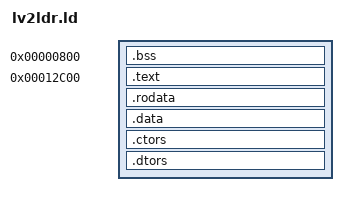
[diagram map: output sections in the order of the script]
ENTRY(_start)

SECTIONS
{
  . = 0x800;

  .bss :
  {
    */lv2ldr/src/loader_global.o(.bss.g_loader)
    */lv2ldr/src/loader_data.o(.bss.g_revoke_list)
    */lv2ldr/src/loader_data.o(.bss.g_auth_area)
    */lv2ldr/src/auth_data.o(.bss.g_revoke_buf)
    */lv2ldr/src/auth_data.o(.bss.g_revoke_digest)
    */lv1ldr/src/auth_buffers.o(.bss.g_part_area)
    */lv1ldr/src/auth_buffers.o(.bss.g_part_digest)
    */lv1ldr/src/auth_buffers.o(.bss.g_header)
    */lv1ldr/src/auth_transfer.o(.bss.g_inf_tail)
    */isoldr/src/hmac_digest.o(.bss.g_hmac)
    */lv1ldr/src/auth_transfer.o(.bss.g_inf_offset)
    */lv1ldr/src/auth_transfer.o(.bss.g_inf_total)
    */lv1ldr/src/auth_transfer.o(.bss.g_inf_out)
    */lv1ldr/src/auth_transfer.o(.bss.g_inf_done)
    */lv1ldr/src/auth_transfer.o(.bss.g_inf_avail)
    */lv1ldr/src/auth_transfer.o(.bss.g_inf_p)
    */isoldr/src/cipher_aes256_cbc.o(.bss.g_aes256_cbc)
    */isoldr/src/cipher_aes128_ctr.o(.bss.g_aes128_ctr)
    *(.bss .bss.* .gnu.linkonce.b.*)
    *(COMMON)
  }

  . = 0x12c00;

  .text :
  {
    */isoldr/src/crt0.o(.text)
    */lv2ldr/src/loader_global.o(.text._Z41__static_initialization_and_destruction_0ii)
    */lv2ldr/src/loader_global.o(.text._GLOBAL__I_g_loader)
    */lv2ldr/src/main.o(.text.main)
    */lv2ldr/src/loader.o(.text._ZN6loaderC1Ev)
    */lv2ldr/src/loader.o(.text._ZN6loaderC2Ev)
    *(.text._ZN17tagged_dma_bufferD1Ev)
    */lv2ldr/src/loader.o(.text._ZN6loader12hash_segmentEv)
    */lv2ldr/src/loader.o(.text._ZN6loader9read_fileEv)
    */lv2ldr/src/loader.o(.text._ZN6loader13load_segmentsEv)
    */lv2ldr/src/loader.o(.text._ZN6loader11load_headerEv)
    */lv2ldr/src/loader.o(.text._ZN6loader17check_revoke_listEv)
    */lv2ldr/src/loader.o(.text._ZN6loader12read_requestEv)
    */lv2ldr/src/loader.o(.text._ZN6loader3runEv)
    */lv2ldr/src/hash_reader.o(.text._Z12bytes_differPKhS0_i)
    */lv2ldr/src/hash_reader.o(.text._ZN11hash_reader10get_digestEPhj)
    */lv2ldr/src/hash_reader.o(.text._ZN11hash_reader4openEyyPP10dma_bufferjPKhj)
    *(.text._ZN11hash_readerD0Ev)
    *(.text._ZN11hash_readerD1Ev)
    */lv2ldr/src/hash_reader.o(.text._ZN11hash_readerC1Ev)
    */lv2ldr/src/hash_reader.o(.text._ZN11hash_readerC2Ev)
    */lv2ldr/src/hash_reader.o(.text._ZN11hash_reader4readEv)
    */lv2ldr/src/auth_checks.o(.text._ZeqRK10auth_flagsS1_)
    */lv2ldr/src/auth_checks.o(.text._ZanRK10auth_flagsS1_)
    */lv2ldr/src/auth_checks.o(.text._ZN13authenticator19check_auth_id_classEyy)
    */lv2ldr/src/auth_checks.o(.text._ZN13authenticator18has_required_flagsEv)
    */lv2ldr/src/auth_checks.o(.text._ZN13authenticator12check_issuerEyy)
    */lv2ldr/src/auth_checks.o(.text._ZN13authenticator9get_stateEPy)
    */lv2ldr/src/auth_checks.o(.text._ZN13authenticator12get_app_infoEP13auth_app_info)
    */lv2ldr/src/auth_checks.o(.text._ZN10auth_state3getEPy)
    */lv1ldr/src/auth_buffers.o(.text._ZN10auth_state4loadEPK10auth_entryy)
    */lv1ldr/src/auth_buffers.o(.text._ZN10auth_stateC1Ev)
    */lv1ldr/src/auth_buffers.o(.text._ZN10auth_stateC2Ev)
    *(.text._ZN6cipher6vslot6EPKv)
    *(.text._ZN6cipher6vslot7EPv)
    */lv2ldr/src/revoke_list.o(.text._ZN11revoke_list4initEv)
    */lv2ldr/src/revoke_list.o(.text._ZN11revoke_list12check_headerEPK18revoke_list_header)
    */lv2ldr/src/revoke_list.o(.text._ZN11revoke_list13check_versionEy)
    *(.text._ZN6cipherD0Ev)
    *(.text._ZN6cipherD1Ev)
    *(.text._ZN6cipherD2Ev)
    */isoldr/src/cipher_aes128_ctr.o(.text._ZN17aes128_ctr_cipherD0Ev)
    */isoldr/src/cipher_aes128_ctr.o(.text._ZN17aes128_ctr_cipherD1Ev)
    */isoldr/src/cipher_aes256_cbc.o(.text._ZN17aes256_cbc_cipherD0Ev)
    */isoldr/src/cipher_aes256_cbc.o(.text._ZN17aes256_cbc_cipherD1Ev)
    *(.text._ZN8verifierD0Ev)
    *(.text._ZN8verifierD1Ev)
    *(.text._ZN8verifierD2Ev)
    */isoldr/src/verifier_ecdsa.o(.text._ZN14ecdsa_verifierD0Ev)
    *(.text._ZN14ecdsa_verifierD1Ev)
    */lv2ldr/src/revoke_list.o(.text._ZN11revoke_list15check_encryptedEPK12auth_section)
    */lv2ldr/src/revoke_list.o(.text._ZN11revoke_list11check_plainEPK12auth_section)
    */lv2ldr/src/revoke_list.o(.text._ZN11revoke_list5parseEv)
    */lv2ldr/src/revoke_list.o(.text._ZN11revoke_list4openEPKhS1_S1_PKj)
    */lv2ldr/src/revoke_list.o(.text._ZN11revoke_list4loadEPKv)
    */lv1ldr/src/authenticator.o(.text._ZN9elf_imageC1Ev)
    */lv1ldr/src/authenticator.o(.text._ZN9elf_image4loadEPKv)
    */lv1ldr/src/authenticator.o(.text._ZN13authenticator10set_offsetEy)
    */lv1ldr/src/authenticator.o(.text._ZN13authenticator14check_app_infoEPK13auth_app_infoj)
    */lv1ldr/src/authenticator.o(.text._ZN13authenticator9check_appEP9sce_imagej)
    */lv1ldr/src/authenticator.o(.text._ZN13authenticator11load_headerEjPKhS1_S1_PKjPP10dma_bufferj)
    */lv1ldr/src/authenticator.o(.text._ZN13authenticator11clear_partsEv)
    */lv1ldr/src/authenticator.o(.text._ZN13authenticatorC1Ev)
    */lv1ldr/src/authenticator.o(.text._ZN13authenticatorC2Ev)
    */lv1ldr/src/authenticator.o(.text._ZN13authenticator19read_program_headerEjP10Elf64_Phdr)
    */lv1ldr/src/authenticator.o(.text._ZN13authenticator15read_elf_headerEP10Elf64_Ehdr)
    */lv1ldr/src/authenticator.o(.text._ZN10auth_block3getEPy)
    */lv1ldr/src/auth_buffers.o(.text._ZN10auth_block4loadEPK10auth_entryy)
    */lv1ldr/src/auth_buffers.o(.text._ZN10auth_blockC1Ev)
    */lv1ldr/src/auth_buffers.o(.text._ZN10auth_blockC2Ev)
    */isoldr/src/hmac_digest.o(.text._ZN11hmac_digestC1Ev)
    */isoldr/src/hmac_digest.o(.text._ZN11hmac_digestC2Ev)
    */isoldr/src/hmac_digest.o(.text._Z41__static_initialization_and_destruction_0ii)
    */isoldr/src/hmac_digest.o(.text._GLOBAL__I_g_hmac)
    */isoldr/src/hmac_digest.o(.text._GLOBAL__D_g_hmac)
    */isoldr/src/hmac_digest.o(.text._ZN11hmac_digest6updateEPKhi)
    */isoldr/src/hmac_digest.o(.text._ZN11hmac_digest5finalEPh)
    */isoldr/src/hmac_digest.o(.text._ZN11hmac_digest4initEPKhj)
    */isoldr/src/hmac_digest.o(.text._ZN11hmac_digest6digestEPKhiPhS1_j)
    */lv2ldr/src/revoke_check.o(.text._ZN11revoke_list10is_revokedEjyy)
    */lv1ldr/src/auth_buffers.o(.text._ZN11header_data5clearEv)
    */lv1ldr/src/auth_buffers.o(.text._ZN9auth_tailC1Ev)
    */lv1ldr/src/auth_buffers.o(.text._ZN9auth_tailC2Ev)
    */lv1ldr/src/auth_segments.o(.text._ZN13authenticator12load_segmentEjjyyPP10dma_bufferiS2_i)
    */lv1ldr/src/auth_transfer.o(.text._ZN13authenticator17transfer_deflatedEy)
    */lv1ldr/src/auth_transfer.o(.text._ZN13authenticator15transfer_storedEv)
    */lv1ldr/src/auth_transfer.o(.text._ZN13authenticator13inflate_pieceEP10dma_bufferyPy)
    */isoldr/src/cipher_aes256_cbc.o(.text._ZN17aes256_cbc_cipherC1Ev)
    */isoldr/src/cipher_aes256_cbc.o(.text._Z41__static_initialization_and_destruction_0ii)
    */isoldr/src/cipher_aes256_cbc.o(.text._GLOBAL__D_g_aes256_cbc)
    */isoldr/src/cipher_aes256_cbc.o(.text._GLOBAL__I_g_aes256_cbc)
    */isoldr/src/cipher_aes256_cbc.o(.text._ZN17aes256_cbc_cipher7decryptEPKviPv)
    */isoldr/src/cipher_aes256_cbc.o(.text._ZN17aes256_cbc_cipher7set_keyEPKhS1_)
    */isoldr/src/cipher_aes128_ctr.o(.text._ZN17aes128_ctr_cipherC1Ev)
    */isoldr/src/cipher_aes128_ctr.o(.text._Z41__static_initialization_and_destruction_0ii)
    */isoldr/src/cipher_aes128_ctr.o(.text._GLOBAL__D_g_aes128_ctr)
    */isoldr/src/cipher_aes128_ctr.o(.text._GLOBAL__I_g_aes128_ctr)
    */isoldr/src/cipher_aes128_ctr.o(.text._ZN17aes128_ctr_cipher7decryptEPKviPv)
    */isoldr/src/cipher_aes128_ctr.o(.text._ZN17aes128_ctr_cipher7set_keyEPKhS1_)
    */lv1ldr/src/auth_buffers.o(.text._ZN13authenticator7prependEPK10dma_bufferj)
    */lv1ldr/src/auth_buffers.o(.text._ZN13authenticator17check_part_digestEPK12auth_section)
    */lv1ldr/src/auth_buffers.o(.text._ZN9auth_sink6appendEPKU8__vectorhS2_)
    */lv1ldr/src/auth_buffers.o(.text._ZN13authenticator10read_partsEv)
    */lv1ldr/src/auth_buffers.o(.text._ZN13authenticator9save_tailEPK10dma_buffer)
    */lv1ldr/src/auth_buffers.o(.text._ZN13authenticator12restore_tailEPK10dma_buffer)
    */isoldr/src/verifier_ecdsa.o(.text._ZN14ecdsa_verifier6verifyEPKhiS1_)
    */isoldr/src/verifier_ecdsa.o(.text._ZN14ecdsa_verifierC1EPKhj)
    */isoldr/src/verifier_ecdsa.o(.text._ZN14ecdsa_verifierC2EPKhj)
    */lv1ldr/src/auth_buffers.o(.text._ZN13authenticator12find_sectionEjjP12auth_section)
    */lv1ldr/src/elf_reader.o(.text._ZN9elf_image10get_headerEP10Elf64_Ehdr)
    */lv1ldr/src/elf_reader.o(.text._ZN9elf_image18get_program_headerEjP10Elf64_Phdr)
    */lv2ldr/src/revoke_scan.o(.text._ZN11revoke_list10scan_pairsEyy)
    */lv2ldr/src/revoke_scan.o(.text._ZN11revoke_list11scan_pairs2Eyy)
    */lv2ldr/src/revoke_scan.o(.text._ZN11revoke_list10scan_rulesEjyy)
    */isoldr/src/dma_queue.o(.text._ZN9dma_queue12enqueue_readEP10dma_buffer)
    */isoldr/src/dma_queue.o(.text._ZN9dma_queue7dequeueEPP10dma_bufferP9list_nodeMS0_FbvE)
    */isoldr/src/dma_queue.o(.text._ZN9dma_queue12dequeue_readEPP10dma_buffer)
    */isoldr/src/dma_queue.o(.text._ZN9dma_queue5drainEP9list_nodeM10dma_bufferFbvE)
    */isoldr/src/dma_queue.o(.text._ZN9dma_queue5closeEv)
    */isoldr/src/dma_queue.o(.text._ZN9dma_queueC1Ev)
    */isoldr/src/dma_queue.o(.text._ZN9dma_queueC2Ev)
    */isoldr/src/dma_queue.o(.text._ZN9dma_queue11add_writtenEP10dma_buffer)
    */isoldr/src/dma_queue.o(.text._ZN9dma_queue13enqueue_writeEP10dma_buffer)
    */isoldr/src/dma_queue.o(.text._ZN9dma_queue13dequeue_writeEPP10dma_buffer)
    */isoldr/src/dma_queue.o(.text._ZN9dma_queue4openEyjyj)
    */isoldr/src/dma_buffer.o(.text._ZN10dma_buffer10set_bufferEjj)
    *(.text._ZN10dma_bufferD0Ev)
    *(.text._ZN10dma_bufferD1Ev)
    *(.text._ZN10dma_bufferD2Ev)
    */isoldr/src/dma_buffer.o(.text._ZN10dma_bufferC1Ev)
    */isoldr/src/dma_buffer.o(.text._ZN10dma_bufferC2Ev)
    */isoldr/src/dma_buffer.o(.text._ZN17tagged_dma_buffer9max_chunkEj)
    */isoldr/src/dma_buffer_io.o(.text._ZN17tagged_dma_bufferD0Ev)
    *(.text._ZN7dma_mfcC1Ev)
    */isoldr/src/dma_buffer.o(.text._Z41__static_initialization_and_destruction_0ii)
    */isoldr/src/dma_buffer.o(.text._GLOBAL__I__ZN10dma_bufferC2Ev)
    */isoldr/src/dma_buffer.o(.text._ZN17tagged_dma_buffer8transferEyyjj)
    */isoldr/src/dma_buffer.o(.text._ZN17tagged_dma_buffer8put_doneEv)
    */isoldr/src/dma_buffer.o(.text._ZN17tagged_dma_buffer8get_doneEv)
    */isoldr/src/dma_buffer.o(.text._ZN17tagged_dma_bufferC1Ej)
    */isoldr/src/dma_buffer.o(.text._ZN17tagged_dma_bufferC2Ej)
    */isoldr/src/dma_buffer_io.o(.text._ZN17tagged_dma_buffer3putEyjPj)
    */isoldr/src/dma_buffer_io.o(.text._ZN17tagged_dma_buffer3getEyjPj)
    */lv0ldr/crypto/aes_modes.o(.text)
    */lv0ldr/crypto/sha1_digest.o(.text)
    */lv0ldr/crypto/hmac_sha1.o(.text)
    */isoldr/crypto/hmac_sha1_once.o(.text)
    */lv0ldr/crypto/aes.o(.text)
    */lv0ldr/crypto/sha1.o(.text)
    */lv0ldr/crypto/sha1_transform.o(.text)
    */lv0ldr/crypto/ecdsa_id.o(.text)
    */lv0ldr/crypto/ec_curves.o(.text)
    */isoldr/crypto/ecdsa.o(.text)
    */lv0ldr/crypto/ec.o(.text)
    */lv0ldr/crypto/ec_mul2.o(.text)
    */lv0ldr/crypto/bn_core.o(.text)
    */lv0ldr/crypto/bn_in_range.o(.text)
    */lv0ldr/crypto/ec_curve_valid.o(.text)
    */lv0ldr/crypto/bn_from_bytes_not.o(.text)
    */isoldr/src/mfc.o(.text._ZN8mfc_baseC1Ev)
    */isoldr/src/mfc.o(.text._ZN8mfc_baseC2Ev)
    */isoldr/src/mfc.o(.text._Z13mbox_in_countv)
    */isoldr/src/mfc.o(.text._Z9mfc_issuejyjjjj)
    */isoldr/src/mfc.o(.text._Z12mfc_tag_donej)
    */isoldr/src/mfc.o(.text._Z12mbox_in_readPj)
    */isoldr/src/mbox_drain.o(.text._Z13mbox_in_drainv)
    */lv0ldr/src/util/cxx_runtime.o(.text._ZdlPv)
    */lv0ldr/src/util/cxx_runtime.o(.text.__cxa_pure_virtual)
    */lv2ldr/src/ch64.o(.text._Z18ch64_request_40000v)
    */lv2ldr/src/ch64.o(.text._Z12ch64_requestv)
    */lv2ldr/src/ch72.o(.text._Z8ch72_putiPKji)
    */lv2ldr/src/ch72.o(.text._Z8ch72_getiPji)
    */lv2ldr/src/ch72.o(.text._Z16ch72_put_requestjPKh)
    */lv2ldr/src/ch72.o(.text._Z14ch72_get_replyPh)
    */lv2ldr/src/ch72.o(.text._Z16ch72_get_versionPy)
    */lv2ldr/src/ch72.o(.text._Z20ch72_compare_versiony)
    */lv2ldr/src/ch72.o(.text._Z11ch72_unwrapPU8__vectorhPKS_iPKhiS2_)
    */lv2ldr/src/ch72.o(.text._Z14ch72_unwrap_ivPU8__vectorhPKS_i)
    */lv2ldr/src/ch72.o(.text._Z15ch72_unwrap_keyPU8__vectorhPKS_i)
    */lv1ldr/src/auth_header.o(.text._ZN9sce_image12get_sectionsEv)
    */lv1ldr/src/auth_header.o(.text._ZN9sce_image17get_section_countEPj)
    */lv1ldr/src/auth_header.o(.text._ZN9sce_image13get_key_countEPj)
    */lv1ldr/src/auth_header.o(.text._ZN9sce_image14get_ext_headerEPjS0_)
    */lv1ldr/src/auth_check.o(.text._Z16check_sce_headerPKU8__vectorhPKvtj)
    */lv1ldr/src/auth_check.o(.text._Z17check_meta_headerPKU8__vectorhPK9auth_metaj)
    */lv1ldr/src/auth_check.o(.text._Z14check_sectionsP9sce_image)
    */lv1ldr/src/auth_check.o(.text._Z18check_control_infoPK12auth_controly)
    */lv1ldr/src/auth_check.o(.text._Z16check_ext_headerP9sce_image)
    */lv1ldr/src/auth_check.o(.text._ZN9sce_image12get_app_infoEPj)
    */lv0ldr/libgcc/umoddi3.o(.text)
    */lv0ldr/src/boot/exit.o(.text.exit)
    */lv0ldr/src/util/memcmp.o(.text.memcmp)
    */isoldr/src/memset.o(.text.memset)
    */isoldr/src/memcpy.o(.text.memcpy)
    */lv1ldr/zlib/lv1ldr_inflate.o(.text.lv1ldr_inflate_end)
    */lv1ldr/zlib/lv1ldr_inflate.o(.text.lv1ldr_inflate_init)
    */lv1ldr/zlib/lv1ldr_inflate.o(.text.lv1ldr_inflate)
    */lv1ldr/zlib/inflate.o(.text.inflateEnd)
    */lv1ldr/zlib/inflate.o(.text.updatewindow)
    */lv1ldr/zlib/inflate.o(.text.inflate)
    */lv1ldr/zlib/inflate.o(.text.inflateInit_)
    */lv1ldr/zlib/inftrees.o(.text.inflate_table)
    */lv1ldr/zlib/adler32.o(.text.adler32)
    */lv1ldr/zlib/zutil.o(.text.zcfree)
    */lv1ldr/zlib/zutil.o(.text.zcalloc)
    */lv1ldr/zlib/inffast.o(.text.inflate_fast)
    */lv1ldr/src/abort.o(.text.abort)
    *(.text .text.* .gnu.linkonce.t.*)
  }

  .rodata :
  {
    */lv2ldr/src/loader.o(.rodata.cst16)
    */lv2ldr/src/loader_data.o(.rodata.g_list_curve)
    */lv2ldr/src/loader_data.o(.rodata.g_lv2_curve)
    */lv2ldr/src/loader_data.o(.rodata.g_segment_key)
    */lv2ldr/src/loader_data.o(.rodata.g_lv2_pub)
    */lv2ldr/src/loader_data.o(.rodata.g_list_pub)
    *(.rodata._ZTV11hash_reader)
    */lv2ldr/src/auth_checks.o(.rodata.cst16)
    */lv2ldr/src/auth_data.o(.rodata.g_required_flags)
    */lv1ldr/src/auth_buffers.o(.rodata.cst16)
    */lv2ldr/src/revoke_list.o(.rodata.cst16)
    *(.rodata._ZTV17aes128_ctr_cipher)
    *(.rodata._ZTV17aes256_cbc_cipher)
    *(.rodata._ZTV6cipher)
    *(.rodata._ZTV14ecdsa_verifier)
    *(.rodata._ZTV8verifier)
    */lv1ldr/src/authenticator.o(.rodata.cst16)
    */lv1ldr/src/auth_transfer.o(.rodata.cst16)
    *(.rodata._ZTV10dma_buffer)
    *(.rodata._ZTV17tagged_dma_buffer)
    */crypto/*.o(.rodata .rodata.*)
    */lv2ldr/src/auth_data.o(.rodata.ch72_key_data)
    */lv2ldr/src/auth_data.o(.rodata.ch72_iv_data)
    */lv2ldr/src/auth_data.o(.rodata.ch72_key_iv)
    */lv2ldr/src/auth_data.o(.rodata.ch72_iv_iv)
    */lv2ldr/src/auth_data.o(.rodata.key_slots)
    */lv2ldr/src/auth_data.o(.rodata.digest_slots)
    */lv2ldr/src/auth_data.o(.rodata.sig_sizes)
    */lv1ldr/src/auth_check.o(.rodata.cst16)
    */lv2ldr/src/auth_data.o(.rodata.control_digest)
    */lv0ldr/src/util/shuffle_table.o(.rodata .rodata.*)
    */lv1ldr/zlib/lv1ldr_inflate.o(.rodata .rodata.*)
    */lv1ldr/zlib/inflate.o(.rodata .rodata.*)
    */lv1ldr/zlib/inftrees.o(.rodata .rodata.*)
    *(.rodata .rodata.* .gnu.linkonce.r.*)
  }

  . = ALIGN(0x80) + (. & (0x80 - 1));
  .data :
  {
    */lv2ldr/src/loader_data.o(.data.g_list_key)
    */lv2ldr/src/loader_data.o(.data.g_list_iv)
    */lv2ldr/src/loader_data.o(.data.g_lv2_key)
    */lv2ldr/src/loader_data.o(.data.g_lv2_iv)
    */lv1ldr/src/auth_transfer.o(.data.g_inf_end)
    *(.data .data.* .gnu.linkonce.d.*)
  }
  .ctors : { KEEP(*(.ctors)) __CTOR_END__ = .; }
  .dtors : { KEEP(*(.dtors)) }

  /DISCARD/ : { *(.comment) *(.note*) *(.eh_frame) }
}
